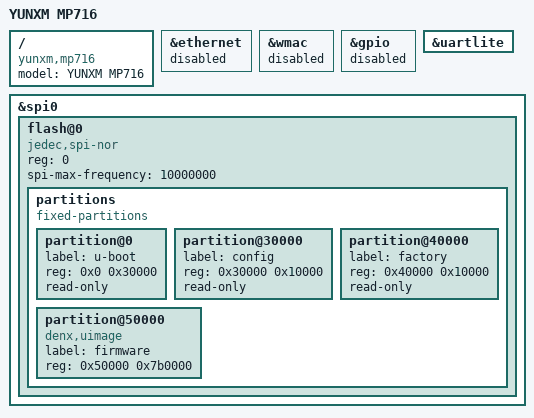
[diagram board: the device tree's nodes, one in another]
// SPDX-License-Identifier: GPL-2.0-or-later OR MIT
//
// Use the MT7628AN evaluation board as the SPI NOR layout reference.
// The MP716 has its own board identity and requires hardware validation.

#include "mt7628an.dtsi"

/ {
	compatible = "yunxm,mp716", "mediatek,mt7628an-soc";
	model = "YUNXM MP716";
	/* Use the SoC memory detection. The MP716 is specified with 64 MiB.
	 * TODO: Confirm detected RAM and the serial console on MP716 hardware.
	 */
};

&ethernet {
	/* TODO: Verify PHY wiring, switch port map and board MAC source. */
	status = "disabled";
};

&wmac {
	/* TODO: Verify the MP716 Factory EEPROM layout and RF calibration. */
	status = "disabled";
};

&gpio {
	/* TODO: Verify button and LED pin numbers and polarity. */
	status = "disabled";
};

/* Inherit serial0 and the ttyS0,57600 console from mt7628an.dtsi. */
&uartlite {
	status = "okay";
};

&spi0 {
	status = "okay";

	flash@0 {
		compatible = "jedec,spi-nor";
		reg = <0>;
		spi-max-frequency = <10000000>;

		partitions {
			compatible = "fixed-partitions";
			#address-cells = <1>;
			#size-cells = <1>;

			partition@0 {
				label = "u-boot";
				reg = <0x0 0x30000>;
				read-only;
			};

			partition@30000 {
				label = "config";
				reg = <0x30000 0x10000>;
				read-only;
			};

			partition@40000 {
				label = "factory";
				reg = <0x40000 0x10000>;
				read-only;
			};

			partition@50000 {
				compatible = "denx,uimage";
				label = "firmware";
				reg = <0x50000 0x7b0000>;
			};
		};
	};
};
